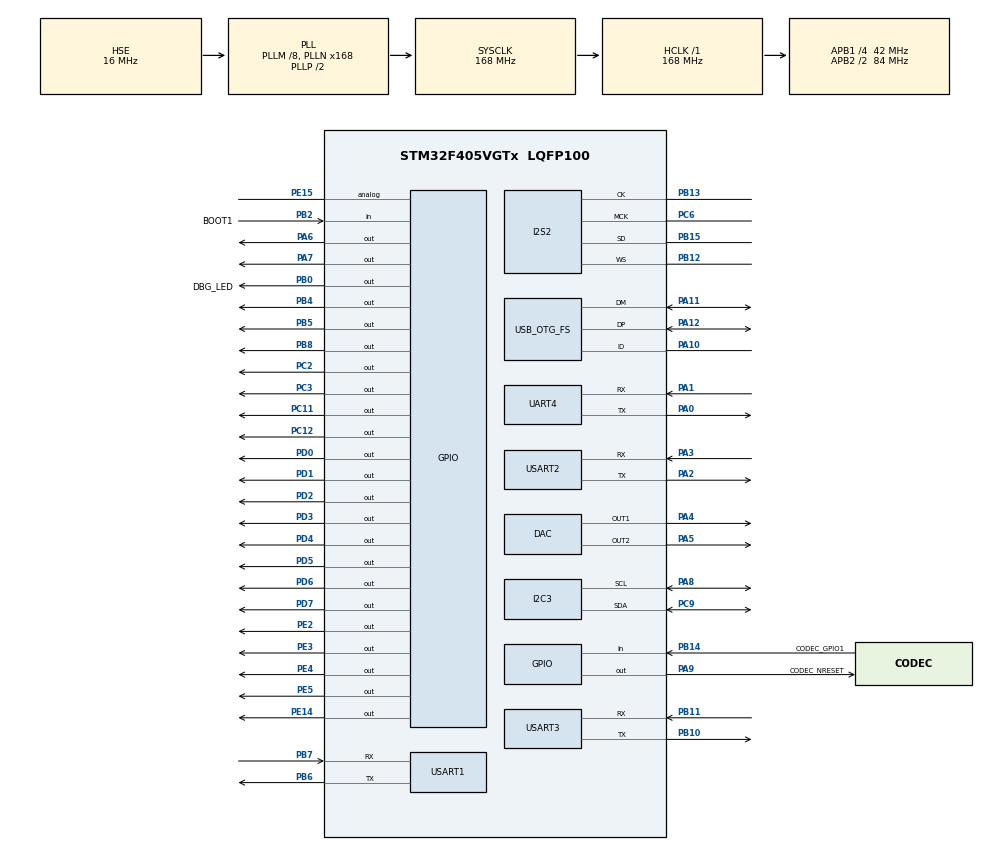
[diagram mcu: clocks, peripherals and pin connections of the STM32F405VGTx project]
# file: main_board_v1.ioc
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I2S2.AudioFreq=I2S_AUDIOFREQ_44K
I2S2.ErrorAudioFreq=10.97 %
I2S2.FullDuplexMode=I2S_FULLDUPLEXMODE_DISABLE
I2S2.Instance=SPI$Index
I2S2.RealAudioFreq=48.828 KHz
I2S2.VirtualMode=I2S_MODE_MASTER
Mcu.Family=STM32F4
Mcu.Name=STM32F405VGTx
Mcu.Package=LQFP100
NVIC.PriorityGroup=NVIC_PRIORITYGROUP_4
PA0-WKUP.Mode=Asynchronous
PA0-WKUP.Signal=UART4_TX
PA1.Mode=Asynchronous
PA1.Signal=UART4_RX
PA10.Mode=OTG/Dual_Role_Device
PA10.Signal=USB_OTG_FS_ID
PA11.Mode=OTG/Dual_Role_Device
PA11.Signal=USB_OTG_FS_DM
PA12.Mode=OTG/Dual_Role_Device
PA12.Signal=USB_OTG_FS_DP
PA13.Mode=Trace_Asynchronous_SW
PA13.Signal=SYS_JTMS-SWDIO
PA14.Mode=Trace_Asynchronous_SW
PA14.Signal=SYS_JTCK-SWCLK
PA2.Mode=Asynchronous
PA2.Signal=USART2_TX
PA3.Mode=Asynchronous
PA3.Signal=USART2_RX
PA4.Signal=COMP_DAC1_group
PA5.Signal=COMP_DAC2_group
PA6.Signal=GPIO_Output
PA7.Signal=GPIO_Output
PA8.Mode=I2C
PA8.Signal=I2C3_SCL
PA9.GPIO_Label=CODEC_NRESET
PA9.Signal=GPIO_Output
PB0.GPIO_Label=DBG_LED
PB0.Signal=GPIO_Output
PB10.Mode=Asynchronous
PB10.Signal=USART3_TX
PB11.Mode=Asynchronous
PB11.Signal=USART3_RX
PB12.Mode=Half_Duplex_Master
PB12.Signal=I2S2_WS
PB13.Mode=Half_Duplex_Master
PB13.Signal=I2S2_CK
PB14.GPIO_Label=CODEC_GPIO1
PB14.Signal=GPIO_Input
PB15.Mode=Half_Duplex_Master
PB15.Signal=I2S2_SD
PB2.GPIO_Label=BOOT1
PB2.Signal=GPIO_Input
PB3.Mode=Trace_Asynchronous_SW
PB3.Signal=SYS_JTDO-SWO
PB4.Signal=GPIO_Output
PB5.Signal=GPIO_Output
PB6.Mode=Asynchronous
PB6.Signal=USART1_TX
PB7.Mode=Asynchronous
PB7.Signal=USART1_RX
PB8.Signal=GPIO_Output
PC11.Signal=GPIO_Output
PC12.Signal=GPIO_Output
PC2.Signal=GPIO_Output
PC3.Signal=GPIO_Output
PC6.Mode=Master_Clock_Activated
PC6.Signal=I2S2_MCK
PC9.Mode=I2C
PC9.Signal=I2C3_SDA
PD0.Signal=GPIO_Output
PD1.Signal=GPIO_Output
PD2.Signal=GPIO_Output
PD3.Signal=GPIO_Output
PD4.Signal=GPIO_Output
PD5.Signal=GPIO_Output
PD6.Signal=GPIO_Output
PD7.Signal=GPIO_Output
PE14.Signal=GPIO_Output
PE15.Signal=GPIO_Analog
PE2.Signal=GPIO_Output
PE3.Signal=GPIO_Output
PE4.Signal=GPIO_Output
PE5.Signal=GPIO_Output
PH0-OSC_IN.Mode=HSE-External-Oscillator
PH0-OSC_IN.Signal=RCC_OSC_IN
PH1-OSC_OUT.Mode=HSE-External-Oscillator
PH1-OSC_OUT.Signal=RCC_OSC_OUT
ProjectManager.HeapSize=0x200
ProjectManager.StackSize=0x400
ProjectManager.TargetToolchain=Makefile
RCC.48MHZClocksFreq_Value=48000000
RCC.AHBFreq_Value=168000000
RCC.APB1CLKDivider=RCC_HCLK_DIV4
RCC.APB1Freq_Value=42000000
RCC.APB1TimFreq_Value=84000000
RCC.APB2CLKDivider=RCC_HCLK_DIV2
RCC.APB2Freq_Value=84000000
RCC.APB2TimFreq_Value=168000000
RCC.CortexFreq_Value=168000000
RCC.HCLKFreq_Value=168000000
RCC.HSE_VALUE=16000000
RCC.HSI_VALUE=16000000
RCC.LSE_VALUE=32768
RCC.PLLI2SN=50
RCC.PLLM=8
RCC.PLLN=168
RCC.PLLQ=7
RCC.SYSCLKFreq_VALUE=168000000
RCC.SYSCLKSource=RCC_SYSCLKSOURCE_PLLCLK
RCC.VCOOutputFreq_Value=336000000
SH.COMP_DAC1_group.0=DAC_OUT1,DAC_OUT1
SH.COMP_DAC2_group.0=DAC_OUT2,DAC_OUT2
UART4.VirtualMode=Asynchronous
USART1.VirtualMode=VM_ASYNC
USART2.VirtualMode=VM_ASYNC
USART3.VirtualMode=VM_ASYNC
board=custom

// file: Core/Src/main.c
/* USER CODE BEGIN Header */
/**
  ******************************************************************************
  * @file           : main.c
  * @brief          : Main program body
  ******************************************************************************
  * @attention
  *
  * Copyright (c) 2023 STMicroelectronics.
  * All rights reserved.
  *
  * This software is licensed under terms that can be found in the LICENSE file
  * in the root directory of this software component.
  * If no LICENSE file comes with this software, it is provided AS-IS.
  *
  ******************************************************************************
  */
/* USER CODE END Header */
#include "main.h"

DAC_HandleTypeDef hdac;

I2C_HandleTypeDef hi2c3;

I2S_HandleTypeDef hi2s2;

UART_HandleTypeDef huart4;
UART_HandleTypeDef huart1;
UART_HandleTypeDef huart2;
UART_HandleTypeDef huart3;

void SystemClock_Config(void);
static void MX_GPIO_Init(void);
static void MX_DAC_Init(void);
static void MX_I2C3_Init(void);
static void MX_I2S2_Init(void);
static void MX_UART4_Init(void);
static void MX_USART1_UART_Init(void);
static void MX_USART2_UART_Init(void);
static void MX_USART3_UART_Init(void);
static void MX_USB_OTG_FS_USB_Init(void);

/* USER CODE BEGIN 0 */

void write_leds(uint16_t val)
{
  HAL_GPIO_WritePin(GPIOE, GPIO_PIN_4, GPIO_PIN_SET);
  HAL_GPIO_WritePin(GPIOE, GPIO_PIN_3, GPIO_PIN_RESET);
  HAL_GPIO_WritePin(GPIOE, GPIO_PIN_5, GPIO_PIN_RESET);

  for(int i = 0; i < 16; i++)
  {
    HAL_GPIO_WritePin(GPIOE, GPIO_PIN_2, val & (0x8000 >> i) ? GPIO_PIN_SET : GPIO_PIN_RESET);
    // HAL_Delay(1);
    HAL_GPIO_WritePin(GPIOE, GPIO_PIN_3, GPIO_PIN_SET);
    // HAL_Delay(1);
    HAL_GPIO_WritePin(GPIOE, GPIO_PIN_3, GPIO_PIN_RESET);
  }
  // HAL_Delay(1);
  HAL_GPIO_WritePin(GPIOE, GPIO_PIN_5, GPIO_PIN_SET);
  // HAL_Delay(1);
  HAL_GPIO_WritePin(GPIOE, GPIO_PIN_5, GPIO_PIN_RESET);
}

/* USER CODE END 0 */

int main(void)
{

  /* MCU Configuration--------------------------------------------------------*/

  /* Reset of all peripherals, Initializes the Flash interface and the Systick. */
  HAL_Init();

  /* Configure the system clock */
  SystemClock_Config();

  /* Initialize all configured peripherals */
  MX_GPIO_Init();
  MX_DAC_Init();
  MX_I2C3_Init();
  MX_I2S2_Init();
  MX_UART4_Init();
  MX_USART1_UART_Init();
  MX_USART2_UART_Init();
  MX_USART3_UART_Init();
  MX_USB_OTG_FS_USB_Init();

  /* Infinite loop */
  /* USER CODE BEGIN WHILE */
  unsigned char test[] = "Hello\r\n";

  int i = 0;
  while (1)
  {
    /* USER CODE END WHILE */
    i++;
    if (i >= 16)
    {
      i = 0;
      HAL_UART_Transmit(&huart3, test, sizeof(test), 10);
    }
    write_leds(1<<i);
    // HAL_GPIO_TogglePin(DBG_LED_GPIO_Port, DBG_LED_Pin);
    HAL_Delay(15);
  }
}

void SystemClock_Config(void)
{
  RCC_OscInitTypeDef RCC_OscInitStruct = {0};
  RCC_ClkInitTypeDef RCC_ClkInitStruct = {0};

  /** Configure the main internal regulator output voltage
  */
  __HAL_RCC_PWR_CLK_ENABLE();
  __HAL_PWR_VOLTAGESCALING_CONFIG(PWR_REGULATOR_VOLTAGE_SCALE1);

  /** Initializes the RCC Oscillators according to the specified parameters
  * in the RCC_OscInitTypeDef structure.
  */
  RCC_OscInitStruct.OscillatorType = RCC_OSCILLATORTYPE_HSE;
  RCC_OscInitStruct.HSEState = RCC_HSE_ON;
  RCC_OscInitStruct.PLL.PLLState = RCC_PLL_ON;
  RCC_OscInitStruct.PLL.PLLSource = RCC_PLLSOURCE_HSE;
  RCC_OscInitStruct.PLL.PLLM = 8;
  RCC_OscInitStruct.PLL.PLLN = 168;
  RCC_OscInitStruct.PLL.PLLP = RCC_PLLP_DIV2;
  RCC_OscInitStruct.PLL.PLLQ = 7;
  if (HAL_RCC_OscConfig(&RCC_OscInitStruct) != HAL_OK)
  {
    Error_Handler();
  }

  /** Initializes the CPU, AHB and APB buses clocks
  */
  RCC_ClkInitStruct.ClockType = RCC_CLOCKTYPE_HCLK|RCC_CLOCKTYPE_SYSCLK
                              |RCC_CLOCKTYPE_PCLK1|RCC_CLOCKTYPE_PCLK2;
  RCC_ClkInitStruct.SYSCLKSource = RCC_SYSCLKSOURCE_PLLCLK;
  RCC_ClkInitStruct.AHBCLKDivider = RCC_SYSCLK_DIV1;
  RCC_ClkInitStruct.APB1CLKDivider = RCC_HCLK_DIV4;
  RCC_ClkInitStruct.APB2CLKDivider = RCC_HCLK_DIV2;

  if (HAL_RCC_ClockConfig(&RCC_ClkInitStruct, FLASH_LATENCY_5) != HAL_OK)
  {
    Error_Handler();
  }
}

static void MX_DAC_Init(void)
{

  DAC_ChannelConfTypeDef sConfig = {0};

  /** DAC Initialization
  */
  hdac.Instance = DAC;
  if (HAL_DAC_Init(&hdac) != HAL_OK)
  {
    Error_Handler();
  }

  /** DAC channel OUT1 config
  */
  sConfig.DAC_Trigger = DAC_TRIGGER_NONE;
  sConfig.DAC_OutputBuffer = DAC_OUTPUTBUFFER_ENABLE;
  if (HAL_DAC_ConfigChannel(&hdac, &sConfig, DAC_CHANNEL_1) != HAL_OK)
  {
    Error_Handler();
  }

  /** DAC channel OUT2 config
  */
  if (HAL_DAC_ConfigChannel(&hdac, &sConfig, DAC_CHANNEL_2) != HAL_OK)
  {
    Error_Handler();
  }

}

static void MX_I2C3_Init(void)
{

  hi2c3.Instance = I2C3;
  hi2c3.Init.ClockSpeed = 100000;
  hi2c3.Init.DutyCycle = I2C_DUTYCYCLE_2;
  hi2c3.Init.OwnAddress1 = 0;
  hi2c3.Init.AddressingMode = I2C_ADDRESSINGMODE_7BIT;
  hi2c3.Init.DualAddressMode = I2C_DUALADDRESS_DISABLE;
  hi2c3.Init.OwnAddress2 = 0;
  hi2c3.Init.GeneralCallMode = I2C_GENERALCALL_DISABLE;
  hi2c3.Init.NoStretchMode = I2C_NOSTRETCH_DISABLE;
  if (HAL_I2C_Init(&hi2c3) != HAL_OK)
  {
    Error_Handler();
  }

}

static void MX_I2S2_Init(void)
{

  hi2s2.Instance = SPI2;
  hi2s2.Init.Mode = I2S_MODE_MASTER_TX;
  hi2s2.Init.Standard = I2S_STANDARD_PHILIPS;
  hi2s2.Init.DataFormat = I2S_DATAFORMAT_16B;
  hi2s2.Init.MCLKOutput = I2S_MCLKOUTPUT_ENABLE;
  hi2s2.Init.AudioFreq = I2S_AUDIOFREQ_44K;
  hi2s2.Init.CPOL = I2S_CPOL_LOW;
  hi2s2.Init.ClockSource = I2S_CLOCK_PLL;
  hi2s2.Init.FullDuplexMode = I2S_FULLDUPLEXMODE_DISABLE;
  if (HAL_I2S_Init(&hi2s2) != HAL_OK)
  {
    Error_Handler();
  }

}

static void MX_UART4_Init(void)
{

  huart4.Instance = UART4;
  huart4.Init.BaudRate = 115200;
  huart4.Init.WordLength = UART_WORDLENGTH_8B;
  huart4.Init.StopBits = UART_STOPBITS_1;
  huart4.Init.Parity = UART_PARITY_NONE;
  huart4.Init.Mode = UART_MODE_TX_RX;
  huart4.Init.HwFlowCtl = UART_HWCONTROL_NONE;
  huart4.Init.OverSampling = UART_OVERSAMPLING_16;
  if (HAL_UART_Init(&huart4) != HAL_OK)
  {
    Error_Handler();
  }

}

static void MX_USART1_UART_Init(void)
{

  huart1.Instance = USART1;
  huart1.Init.BaudRate = 115200;
  huart1.Init.WordLength = UART_WORDLENGTH_8B;
  huart1.Init.StopBits = UART_STOPBITS_1;
  huart1.Init.Parity = UART_PARITY_NONE;
  huart1.Init.Mode = UART_MODE_TX_RX;
  huart1.Init.HwFlowCtl = UART_HWCONTROL_NONE;
  huart1.Init.OverSampling = UART_OVERSAMPLING_16;
  if (HAL_UART_Init(&huart1) != HAL_OK)
  {
    Error_Handler();
  }

}

static void MX_USART2_UART_Init(void)
{

  huart2.Instance = USART2;
  huart2.Init.BaudRate = 115200;
  huart2.Init.WordLength = UART_WORDLENGTH_8B;
  huart2.Init.StopBits = UART_STOPBITS_1;
  huart2.Init.Parity = UART_PARITY_NONE;
  huart2.Init.Mode = UART_MODE_TX_RX;
  huart2.Init.HwFlowCtl = UART_HWCONTROL_NONE;
  huart2.Init.OverSampling = UART_OVERSAMPLING_16;
  if (HAL_UART_Init(&huart2) != HAL_OK)
  {
    Error_Handler();
  }

}

static void MX_USART3_UART_Init(void)
{

  huart3.Instance = USART3;
  huart3.Init.BaudRate = 115200;
  huart3.Init.WordLength = UART_WORDLENGTH_8B;
  huart3.Init.StopBits = UART_STOPBITS_1;
  huart3.Init.Parity = UART_PARITY_NONE;
  huart3.Init.Mode = UART_MODE_TX_RX;
  huart3.Init.HwFlowCtl = UART_HWCONTROL_NONE;
  huart3.Init.OverSampling = UART_OVERSAMPLING_16;
  if (HAL_UART_Init(&huart3) != HAL_OK)
  {
    Error_Handler();
  }

}

static void MX_USB_OTG_FS_USB_Init(void)
{

}

static void MX_GPIO_Init(void)
{
  GPIO_InitTypeDef GPIO_InitStruct = {0};

  /* GPIO Ports Clock Enable */
  __HAL_RCC_GPIOE_CLK_ENABLE();
  __HAL_RCC_GPIOH_CLK_ENABLE();
  __HAL_RCC_GPIOC_CLK_ENABLE();
  __HAL_RCC_GPIOA_CLK_ENABLE();
  __HAL_RCC_GPIOB_CLK_ENABLE();
  __HAL_RCC_GPIOD_CLK_ENABLE();

  /*Configure GPIO pin Output Level */
  HAL_GPIO_WritePin(GPIOE, GPIO_PIN_2|GPIO_PIN_3|GPIO_PIN_4|GPIO_PIN_5
                          |GPIO_PIN_14, GPIO_PIN_RESET);

  /*Configure GPIO pin Output Level */
  HAL_GPIO_WritePin(GPIOC, GPIO_PIN_2|GPIO_PIN_3|GPIO_PIN_11|GPIO_PIN_12, GPIO_PIN_RESET);

  /*Configure GPIO pin Output Level */
  HAL_GPIO_WritePin(GPIOA, GPIO_PIN_6|GPIO_PIN_7|CODEC_NRESET_Pin, GPIO_PIN_RESET);

  /*Configure GPIO pin Output Level */
  HAL_GPIO_WritePin(GPIOB, DBG_LED_Pin|GPIO_PIN_4|GPIO_PIN_5|GPIO_PIN_8, GPIO_PIN_RESET);

  /*Configure GPIO pin Output Level */
  HAL_GPIO_WritePin(GPIOD, GPIO_PIN_0|GPIO_PIN_1|GPIO_PIN_2|GPIO_PIN_3
                          |GPIO_PIN_4|GPIO_PIN_5|GPIO_PIN_6|GPIO_PIN_7, GPIO_PIN_RESET);

  /*Configure GPIO pins : PE2 PE3 PE4 PE5
                           PE14 */
  GPIO_InitStruct.Pin = GPIO_PIN_2|GPIO_PIN_3|GPIO_PIN_4|GPIO_PIN_5
                          |GPIO_PIN_14;
  GPIO_InitStruct.Mode = GPIO_MODE_OUTPUT_PP;
  GPIO_InitStruct.Pull = GPIO_NOPULL;
  GPIO_InitStruct.Speed = GPIO_SPEED_FREQ_LOW;
  HAL_GPIO_Init(GPIOE, &GPIO_InitStruct);

  /*Configure GPIO pins : PC2 PC3 PC11 PC12 */
  GPIO_InitStruct.Pin = GPIO_PIN_2|GPIO_PIN_3|GPIO_PIN_11|GPIO_PIN_12;
  GPIO_InitStruct.Mode = GPIO_MODE_OUTPUT_PP;
  GPIO_InitStruct.Pull = GPIO_NOPULL;
  GPIO_InitStruct.Speed = GPIO_SPEED_FREQ_LOW;
  HAL_GPIO_Init(GPIOC, &GPIO_InitStruct);

  /*Configure GPIO pins : PA6 PA7 CODEC_NRESET_Pin */
  GPIO_InitStruct.Pin = GPIO_PIN_6|GPIO_PIN_7|CODEC_NRESET_Pin;
  GPIO_InitStruct.Mode = GPIO_MODE_OUTPUT_PP;
  GPIO_InitStruct.Pull = GPIO_NOPULL;
  GPIO_InitStruct.Speed = GPIO_SPEED_FREQ_LOW;
  HAL_GPIO_Init(GPIOA, &GPIO_InitStruct);

  /*Configure GPIO pins : DBG_LED_Pin PB4 PB5 PB8 */
  GPIO_InitStruct.Pin = DBG_LED_Pin|GPIO_PIN_4|GPIO_PIN_5|GPIO_PIN_8;
  GPIO_InitStruct.Mode = GPIO_MODE_OUTPUT_PP;
  GPIO_InitStruct.Pull = GPIO_NOPULL;
  GPIO_InitStruct.Speed = GPIO_SPEED_FREQ_LOW;
  HAL_GPIO_Init(GPIOB, &GPIO_InitStruct);

  /*Configure GPIO pins : BOOT1_Pin CODEC_GPIO1_Pin */
  GPIO_InitStruct.Pin = BOOT1_Pin|CODEC_GPIO1_Pin;
  GPIO_InitStruct.Mode = GPIO_MODE_INPUT;
  GPIO_InitStruct.Pull = GPIO_NOPULL;
  HAL_GPIO_Init(GPIOB, &GPIO_InitStruct);

  /*Configure GPIO pin : PE15 */
  GPIO_InitStruct.Pin = GPIO_PIN_15;
  GPIO_InitStruct.Mode = GPIO_MODE_ANALOG;
  GPIO_InitStruct.Pull = GPIO_NOPULL;
  HAL_GPIO_Init(GPIOE, &GPIO_InitStruct);

  /*Configure GPIO pins : PA10 PA11 PA12 */
  GPIO_InitStruct.Pin = GPIO_PIN_10|GPIO_PIN_11|GPIO_PIN_12;
  GPIO_InitStruct.Mode = GPIO_MODE_AF_PP;
  GPIO_InitStruct.Pull = GPIO_NOPULL;
  GPIO_InitStruct.Speed = GPIO_SPEED_FREQ_VERY_HIGH;
  GPIO_InitStruct.Alternate = GPIO_AF10_OTG_FS;
  HAL_GPIO_Init(GPIOA, &GPIO_InitStruct);

  /*Configure GPIO pins : PD0 PD1 PD2 PD3
                           PD4 PD5 PD6 PD7 */
  GPIO_InitStruct.Pin = GPIO_PIN_0|GPIO_PIN_1|GPIO_PIN_2|GPIO_PIN_3
                          |GPIO_PIN_4|GPIO_PIN_5|GPIO_PIN_6|GPIO_PIN_7;
  GPIO_InitStruct.Mode = GPIO_MODE_OUTPUT_PP;
  GPIO_InitStruct.Pull = GPIO_NOPULL;
  GPIO_InitStruct.Speed = GPIO_SPEED_FREQ_LOW;
  HAL_GPIO_Init(GPIOD, &GPIO_InitStruct);

}

void Error_Handler(void)
{
  __disable_irq();
  while (1)
  {
  }
}
